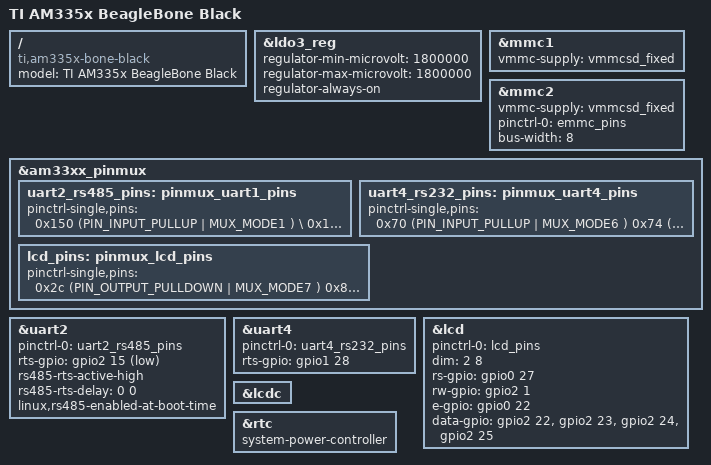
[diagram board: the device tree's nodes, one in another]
/*
 * Copyright (C) 2012 Texas Instruments Incorporated - http://www.ti.com/
 *
 * This program is free software; you can redistribute it and/or modify
 * it under the terms of the GNU General Public License version 2 as
 * published by the Free Software Foundation.
 */
/dts-v1/;

#include "am33xx.dtsi"
#include "am335x-bone-common.dtsi"

/ {
	model = "TI AM335x BeagleBone Black";
	compatible = "ti,am335x-bone-black", "ti,am335x-bone", "ti,am33xx";
};

&ldo3_reg {
	regulator-min-microvolt = <1800000>;
	regulator-max-microvolt = <1800000>;
	regulator-always-on;
};

&mmc1 {
	vmmc-supply = <&vmmcsd_fixed>;
};

&mmc2 {
	vmmc-supply = <&vmmcsd_fixed>;
	pinctrl-names = "default";
	pinctrl-0 = <&emmc_pins>;
	bus-width = <8>;
	status = "okay";
};

&am33xx_pinmux {
        uart2_rs485_pins: pinmux_uart1_pins {
            pinctrl-single,pins = <
                0x150 (PIN_INPUT_PULLUP | MUX_MODE1 ) /* spi0_sckl.uart2_rxd */\
                0x154 (PIN_OUTPUT_PULLDOWN | MUX_MODE1 ) /* spi0_d0.uart2_txd */\
                0xc4  (PIN_OUTPUT_PULLDOWN | MUX_MODE7 ) /* lcd_data9.uart2_rtsn */
            >;
        };

        uart4_rs232_pins: pinmux_uart4_pins {
            pinctrl-single,pins = <
                0x70 (PIN_INPUT_PULLUP | MUX_MODE6 ) /* uart4_rxd_mux2 */
                0x74 (PIN_OUTPUT_PULLDOWN | MUX_MODE6 ) /* uart4_txd_mux2 */
                0x78 (PIN_OUTPUT_PULLDOWN | MUX_MODE7 ) /* gpio1[28] rts */
                0x40 (PIN_INPUT_PULLDOWN | MUX_MODE7 ) /* gpio1[16] cts */
            >;
        };

        lcd_pins: pinmux_lcd_pins {
            pinctrl-single,pins = <
                0x2c (PIN_OUTPUT_PULLDOWN | MUX_MODE7 ) /* RS  gpio0[27] P8_17 */
                0x8c (PIN_OUTPUT_PULLDOWN | MUX_MODE7 ) /* R/W gpio2[1]  P8_18 */
                0x20 (PIN_OUTPUT_PULLDOWN | MUX_MODE7 ) /* E   gpio0[22] P8_19 */
                0xe0 (PIN_OUTPUT_PULLDOWN | MUX_MODE7 ) /* DB4 gpio2[22] P8_27 */
                0xe4 (PIN_OUTPUT_PULLDOWN | MUX_MODE7 ) /* DB5 gpio2[23] P8_29 */
                0xe8 (PIN_OUTPUT_PULLDOWN | MUX_MODE7 ) /* DB6 gpio2[24] P8_28 */
                0xec (PIN_OUTPUT_PULLDOWN | MUX_MODE7 ) /* DB7 gpio2[25] P8_30 */
            >;
        };
};

&uart2 {
	pinctrl-names = "default";
	pinctrl-0 = <&uart2_rs485_pins>;

	rts-gpio = <&gpio2 15 GPIO_ACTIVE_LOW>;
	rs485-rts-active-high; /* undocumented of flag */
	rs485-rts-delay = <0 0>;
	linux,rs485-enabled-at-boot-time;

	status = "okay";
};

&uart4 {
	pinctrl-names = "default";
	pinctrl-0 = <&uart4_rs232_pins>;

	rts-gpio = <&gpio1 28 GPIO_ACTIVE_HIGH>;

	status = "okay";
};

&lcd {
    pinctrl-names = "default";
    pinctrl-0 = <&lcd_pins>;
    dim = <2 8>;
    rs-gpio = <&gpio0 27 GPIO_ACTIVE_HIGH>;
    rw-gpio = <&gpio2 1 GPIO_ACTIVE_HIGH>;
    e-gpio = <&gpio0 22 GPIO_ACTIVE_HIGH>;
    data-gpio = <
        &gpio2 22 GPIO_ACTIVE_HIGH /* DB4 */
        &gpio2 23 GPIO_ACTIVE_HIGH /* DB5 */
        &gpio2 24 GPIO_ACTIVE_HIGH /* DB6 */
        &gpio2 25 GPIO_ACTIVE_HIGH /* DB7 */
    >;
};

&lcdc {
	status = "okay";
};

&rtc {
	system-power-controller;
};
